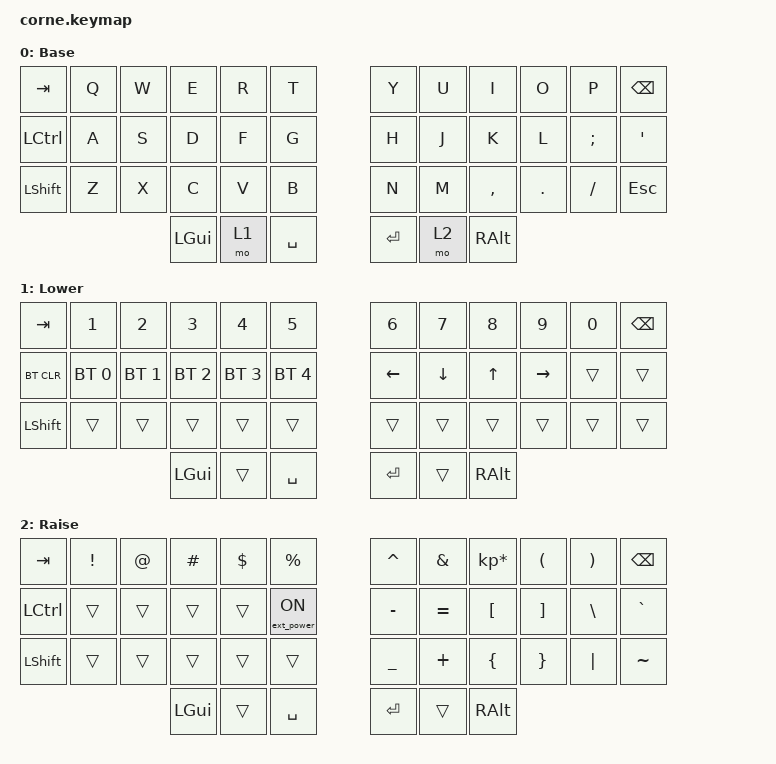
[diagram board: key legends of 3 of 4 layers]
/*
 * Copyright (c) 2020 The ZMK Contributors
 *
 * SPDX-License-Identifier: MIT
 */

#include <behaviors.dtsi>
#include <dt-bindings/zmk/keys.h>
#include <dt-bindings/zmk/bt.h>
#include <dt-bindings/zmk/rgb.h>
#include <dt-bindings/zmk/outputs.h>
#include <dt-bindings/zmk/ext_power.h>
#include <dt-bindings/led/led.h>


// Layers
#define _QWERTY      0
#define _LOWER       1
#define _RAISE       2
#define _SPACE       3
#define _NAVIGATION  4
#define _ADJUST      5


/ {
        keymap {
                compatible = "zmk,keymap";

                default_layer {
// -----------------------------------------------------------------------------------------
// |  TAB |  Q  |  W  |  E  |  R  |  T  |   |  Y  |  U   |  I  |  O  |  P  | BKSP |
// | CTRL |  A  |  S  |  D  |  F  |  G  |   |  H  |  J   |  K  |  L  |  ;  |  '   |
// | SHFT |  Z  |  X  |  C  |  V  |  B  |   |  N  |  M   |  ,  |  .  |  /  | ESC  |
//                    | GUI | LWR | SPC |   | ENT | RSE  | ALT |
                        display-name = "Base";
                        bindings = <
   &kp TAB   &kp Q &kp W &kp E &kp R &kp T   &kp Y &kp U  &kp I     &kp O   &kp P    &kp BSPC
   &kp LCTRL &kp A &kp S &kp D &kp F &kp G   &kp H &kp J  &kp K     &kp L   &kp SEMI &kp SQT
   &kp LSHFT &kp Z &kp X &kp C &kp V &kp B   &kp N &kp M  &kp COMMA &kp DOT &kp FSLH &kp ESC
                  &kp LGUI &mo 1 &kp SPACE   &kp RET &mo 2 &kp RALT
                        >;
                };
                lower_layer {
// -----------------------------------------------------------------------------------------
// |  TAB |  1  |  2  |  3  |  4  |  5  |   |  6  |  7  |  8  |  9  |  0  | BKSP |
// | BTCLR| BT1 | BT2 | BT3 | BT4 | BT5 |   | LFT | DWN |  UP | RGT |     |      |
// | SHFT |     |     |     |     |     |   |     |     |     |     |     |      |
//                    | GUI |     | SPC |   | ENT |     | ALT |
                        display-name = "Lower";
                        bindings = <
   &kp TAB    &kp N1       &kp N2       &kp N3       &kp N4       &kp N5         &kp N6   &kp N7   &kp N8 &kp N9    &kp N0 &kp BSPC
   &bt BT_CLR &bt BT_SEL 0 &bt BT_SEL 1 &bt BT_SEL 2 &bt BT_SEL 3 &bt BT_SEL 4   &kp LEFT &kp DOWN &kp UP &kp RIGHT &trans &trans
   &kp LSHFT  &trans       &trans       &trans       &trans       &trans         &trans   &trans   &trans &trans    &trans &trans
                          	        &kp LGUI     &trans       &kp SPACE      &kp RET  &trans   &kp RALT
                        >;
                };

                raise_layer {
// -----------------------------------------------------------------------------------------
// |  TAB |  !  |  @  |  #  |  $  |  %  |   |  ^  |  &  |  *  |  (  |  )  | BKSP |
// | CTRL |     |     |     |     |     |   |  -  |  =  |  [  |  ]  |  \  |  `   |
// | SHFT |     |     |     |     |     |   |  _  |  +  |  {  |  }  | "|" |  ~   |
//                    | GUI |     | SPC |   | ENT |     | ALT |
                        display-name = "Raise";
                        bindings = <
   &kp  TAB  &kp EXCL &kp AT &kp HASH &kp DLLR &kp PRCNT             &kp CARET &kp AMPS  &kp KP_MULTIPLY &kp LPAR &kp RPAR &kp BSPC
   &kp LCTRL &trans   &trans &trans   &trans   &ext_power EP_ON      &kp MINUS &kp EQUAL &kp LBKT        &kp RBKT &kp BSLH &kp GRAVE
   &kp LSHFT &trans   &trans &trans   &trans   &trans      &kp UNDER &kp PLUS  &kp LBRC        &kp RBRC &kp PIPE &kp TILDE
                    	     &kp LGUI &trans   &kp SPACE   &kp RET   &trans    &kp RALT
                        >;
                };

                extra_1 {
                        status = "reserved";
                };

                extra_2 {
                        status = "reserved";
                };

                extra_3 {
                        status = "reserved";
                };

                adjust_layer {
                        display-name = "Adjust";
                        bindings = <
                        &rgb_ug RGB_BRI &rgb_ug RGB_SAI &rgb_ug RGB_HUI &rgb_ug RGB_EFF &none &rgb_ug RGB_TOG              &bt BT_SEL 0     &bt BT_SEL 1  &bt BT_SEL 2 &bt BT_SEL 3       &bt BT_SEL 4        &bt BT_CLR
                        &rgb_ug RGB_BRD &rgb_ug RGB_SAD &rgb_ug RGB_HUD &rgb_ug RGB_EFR &none &none                        &none            &none         &none        &ext_power EP_ON   &ext_power EP_OFF   &ext_power EP_TOG
                        &none           &none           &none           &none           &none &none                        &sys_reset       &bootloader   &none        &out OUT_USB       &out OUT_BLE        &out OUT_TOG
                                                                  &trans      &trans       &trans        &trans      &trans
                        >;
                };
        };
};

